# Sonata System register map
Vendor: lowRISC; File version: 0.1
CPU: Ibex r0p1, little endian, no MPU, no FPU, VTOR, 2 interrupt priority bits, 1 interrupts
Registers are 32-bit, read-write, no defined reset value unless marked. A register's access mark holds for its fields unless they carry their own. Offsets are from the block's base; [hi:lo] are bit positions.

## SPI0
Base 0x80302000
Same registers: SPI_LCD 0x80300000, SPI_ETHERNET 0x80301000, SPI1 0x80303000, SPI2 0x80304000
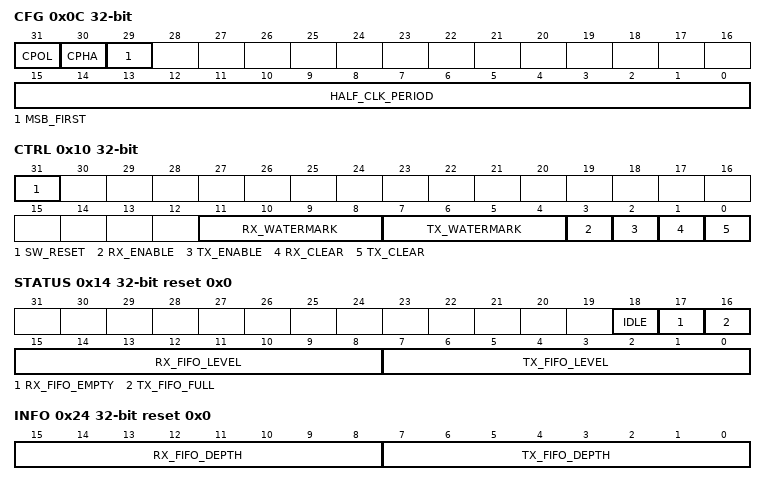
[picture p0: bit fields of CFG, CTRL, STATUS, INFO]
0x0C CFG — Configuration register
  [31] CPOL — The polarity of the spi_clk signal. When CPOL is 0 clock is low when idle and the leading edge is positive. When CPOL is 1 clock is high when idle and the leading edge is negative
  [30] CPHA — The phase of the spi_clk signal. When CPHA is 0 data is sampled on the leading edge and changes on the trailing edge. The first data bit is immediately available before the first leading edge of the clock when transmission begins. When CPHA is 1 data is sampled on the trailing edge and change on the leading edge.
  [29] MSB_FIRST — When set the most significant bit (MSB) is the first bit sent and received with each byte
  [15:0] HALF_CLK_PERIOD — The length of a half period (i.e. positive edge to negative edge) of the SPI clock, measured in system clock cycles reduced by 1. At the standard Sonata 50 MHz system clock a value of 0 gives a 25 MHz SPI clock, a value of 1 gives a 12.5 MHz SPI clock, a value of 2 gives a 8.33 MHz SPI clock and so on.
0x10 CTRL — SPI control register
  [31] SW_RESET — Software reset perfomed when written 1.
  [11:8] RX_WATERMARK — The watermark level for the receive FIFO, depending on the value the interrupt will trigger at different points: 0: 1 or more items in the FIFO. 1: 2 or more items in the FIFO. 2: 4 or more items in the FIFO. 3: 8 or more items in the FIFO. 4: 16 or more items in the FIFO. 5: 32 or more items in the FIFO. 6: 56 or more items in the FIFO
  [7:4] TX_WATERMARK — The watermark level for the transmit FIFO, depending on the value the interrupt will trigger at different points: 0: 1 or fewer items in the FIFO. 1: 2 or fewer items in the FIFO. 2: 4 or fewer items in the FIFO. 3: 8 or fewer items in the FIFO. 4: 16 or fewer items in the FIFO
  [3] RX_ENABLE — When set incoming bits are written to the receive FIFO. When clear incoming bits are ignored.
  [2] TX_ENABLE — When set bytes from the transmit FIFO are sent. When clear the state of the outgoing spi_cipo is undefined whilst the SPI clock is running.
  [1] RX_CLEAR — Write 1 to clear the receive FIFO.
  [0] TX_CLEAR — Write 1 to clear the transmit FIFO.
0x14 STATUS ro reset 0x0 — SPI Status Register
  [18] IDLE — When set the SPI block is idle and can accept a new start command.
  [17] RX_FIFO_EMPTY — When set the receive FIFO is empty and any data read from it will be undefined.
  [16] TX_FIFO_FULL — When set the transmit FIFO is full and any data written to it will be ignored.
  [15:8] RX_FIFO_LEVEL — Number of items in the receive FIFO
  [7:0] TX_FIFO_LEVEL — Number of items in the transmit FIFO
0x18 START wo reset 0x0 — When written begins an SPI operation. Writes are ignored when the SPI block is active.
  [10:0] BYTE_COUNT — Number of bytes to receive/transmit in the SPI operation
0x1C RX_FIFO ro reset 0x0 — Data from the receive FIFO
  [7:0] DATA — Byte popped from the FIFO.
0x20 TX_FIFO wo reset 0x0 — Bytes written here are pushed to the transmit FIFO
  [7:0] DATA — Byte to be push to the FIFO.
0x24 INFO ro reset 0x0 — Bytes written here are pushed to the transmit FIFO
  [15:8] RX_FIFO_DEPTH — Maximum number of items in the receive FIFO.
  [7:0] TX_FIFO_DEPTH — Maximum number of items in the transmit FIFO.
0x28 CS reset 0x0 — Specifies which peripherals are selected for transmit/receive operations. An operation may select multiple peripherals simultaneously but this functionality shall be used only for transmit operations. This register shall be changed only when the SPI controller is idle, not whilst a transmit/receive operation may be in progress.
  [3:0] CS — These bits are zero when the corresponding peripheral is selected for transmit/receive operations.

## PWM0 — Simple PWM0
Base 0x80001000
Same registers: PWM1 0x80001008, PWM2 0x80001010, PWM3 0x80001018, PWM4 0x80001020, PWM5 0x80001028, PWM_LCD 0x80001030
0x00 WIDTH 8-bit reset 0x0 — PWM width
  [7:0] VALUE — Pwm width.
0x04 COUNTER 8-bit reset 0x0 — PWM counter
  [7:0] VALUE — Pwm counter.

## TIMER0 — Controls timer
Base 0x80040000
0x4000 MTIMECMPL reset 0x0 — mtime cmp low
  [31:0] VALUE
0x4004 MTIMECMPH reset 0x0 — mtime cmp high
  [31:0] VALUE
0xBFF8 MTIMEL reset 0x0 — mtime low
  [31:0] VALUE
0xBFFC MTIMEH reset 0x0 — mtime high
  [31:0] VALUE

## GPIO0 — Gpio port a
Base 0x80000000
Same registers: GPIO_RPI 0x80000040, GPIO_ARDUINO 0x80000080, GPIO_PMOD0 0x800000C0, GPIO_PMOD1 0x80000100, GPIO_PMODC 0x80000140
0x00 OUT wo reset 0x0 — Write to control the gpio state
  [31:0] PINS
0x04 IN ro reset 0x0 — Read the gpio state
  [31:0] PINS
0x08 IN_DBNC ro reset 0x0 — DBNC
  [31:0] VALUE — DBNC.
0x0C OUTPUT_ENABLE reset 0x0 — Not used
  [31:0] VALUE — val
